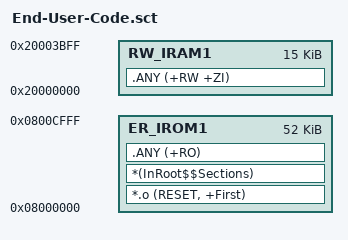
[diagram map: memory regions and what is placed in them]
; *************************************************************
; *** Scatter-Loading Description File generated by uVision ***
; *************************************************************

LR_IROM1 0x08000000 0x0000D000  {    ; load region size_region
  ER_IROM1 0x08000000 0x0000D000  {  ; load address = execution address
   *.o (RESET, +First)
   *(InRoot$$Sections)
   .ANY (+RO)
  }
  RW_IRAM1 0x20000000 0x00003C00  {  ; RW data
   .ANY (+RW +ZI)
  }
  
  ; 0x20003C00 ~ 0x20003FFF  1K RAM reserved for SLIB code
}

; 0x0800D000 ~ 0x0800FFFF reserved for SLIB protected area



